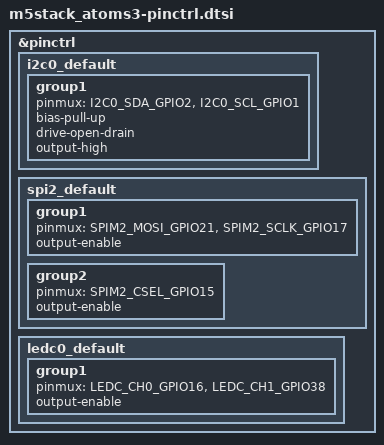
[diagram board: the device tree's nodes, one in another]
#include <zephyr/dt-bindings/pinctrl/esp32s3-pinctrl.h>

&pinctrl {
	/* ── I2C0: SDA=GPIO2, SCL=GPIO1 (Grove PORT-A) ──────────────────── */
	i2c0_default: i2c0_default {
		group1 {
			pinmux = <I2C0_SDA_GPIO2>,
			         <I2C0_SCL_GPIO1>;
			bias-pull-up;
			drive-open-drain;
			output-high;
		};
	};

	/* ── SPI2: MOSI=GPIO21, SCK=GPIO17, CS=GPIO15 (display) ─────────── */
	spi2_default: spi2_default {
		group1 {
			pinmux = <SPIM2_MOSI_GPIO21>,
			         <SPIM2_SCLK_GPIO17>;
			output-enable;
		};
		group2 {
			pinmux = <SPIM2_CSEL_GPIO15>;
			output-enable;
		};
	};

	/* ── LEDC: CH0=GPIO16 (backlight), CH1=GPIO38 (buzzer) ─────────── */
	ledc0_default: ledc0_default {
		group1 {
			pinmux = <LEDC_CH0_GPIO16>,
			         <LEDC_CH1_GPIO38>;
			output-enable;
		};
	};
};
